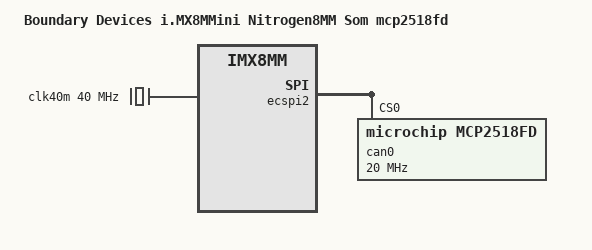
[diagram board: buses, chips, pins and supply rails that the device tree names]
// SPDX-License-Identifier: (GPL-2.0+ OR MIT)
/*
 * Copyright 2020 Boundary Devices
 */

#include "imx8mm-nitrogen8mm_som.dts"

&iomuxc {
	/delete-node/ i2c3-ov5640-mipigrp;

	pinctrl_ecspi2_mcp2518fd: ecspi2-mcp2518fdgrp {
		fsl,pins = <
#define GPIRQ_MCP2518FD		<&gpio1 5 IRQ_TYPE_LEVEL_LOW>
			MX8MMN(IOMUXC_GPIO1_IO05_GPIO1_IO5, 0x19)
		>;
	};
};

/ {
	model = "Boundary Devices i.MX8MMini Nitrogen8MM Som mcp2518fd";

	clocks {
		/delete-node/ clk16m;
		clk40m: clk40m {
			compatible = "fixed-clock";
			#clock-cells = <0>;
			clock-frequency = <40000000>;
		};
	};
};

&ecspi2 {
	/delete-node/ spidev@0;

	can0: can@0 {
		clocks = <&clk40m>;
		compatible = "microchip,mcp2518fd";
		interrupts-extended = GPIRQ_MCP2518FD;
		pinctrl-names = "default";
		pinctrl-0 = <&pinctrl_ecspi2_mcp2518fd>;
		reg = <0>;
		spi-max-frequency = <20000000>;
	};
};

/delete-node/ &csi1_bridge;

&i2c3 {
	/delete-node/ ov5640-mipi1@3c;
};

/delete-node/ &mipi_csi_1;
